# M3V4 register map
File version: 0.1
Registers are 32-bit, read-write, reset 0x0 unless marked. A register's access mark holds for its fields unless they carry their own. Offsets are from the block's base; [hi:lo] are bit positions; {n}, {i} and the like mark numbered series.

## PE — General Purpose Input_Output Port (PE)
Base 0x40000100
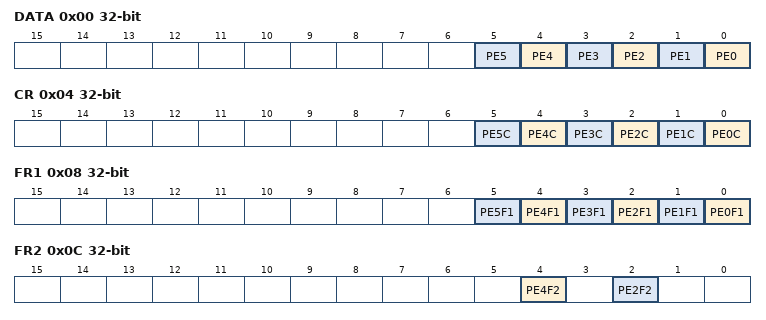
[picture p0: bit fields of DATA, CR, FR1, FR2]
0x00 DATA — PE Data Register
  [n] PE{n} (n=0..5)
0x04 CR — PE Control Register
  [n] PE{n}C (n=0..5)
0x08 FR1 — PE Function Register 1
  [n] PE{n}F1 (n=0..5)
0x0C FR2 — PE Function Register 2
  [4] PE4F2, [2] PE2F2
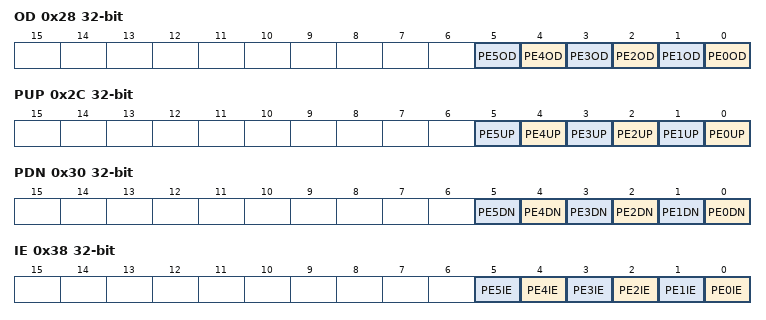
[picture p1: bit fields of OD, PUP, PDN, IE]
0x28 OD — PE Open Drain Control Register
  [n] PE{n}OD (n=0..5)
0x2C PUP — PE Pull-Up Control Register
  [n] PE{n}UP (n=0..5)
0x30 PDN — PE Pull-Down Control Register
  [n] PE{n}DN (n=0..5)
0x38 IE — PE Input Enable Control Register
  [n] PE{n}IE (n=0..5)

## PF — General Purpose Input_Output Port (PF)
Base 0x40000140
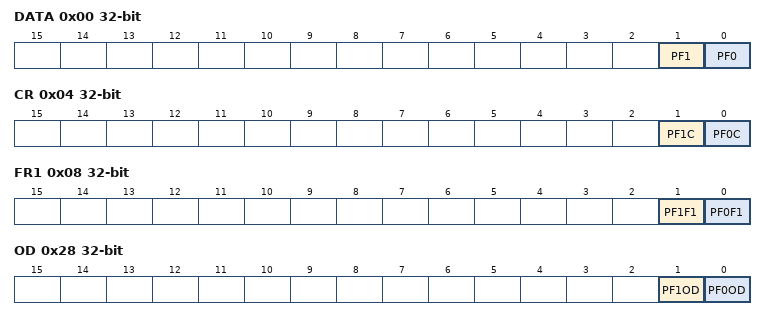
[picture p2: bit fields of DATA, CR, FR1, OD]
0x00 DATA — PF Data Register
  [1] PF1, [0] PF0
0x04 CR — PF Control Register
  [1] PF1C, [0] PF0C
0x08 FR1 — PF Function Register 1
  [1] PF1F1, [0] PF0F1
0x0C FR2 — PF Function Register 2
  [1] PF1F2
0x28 OD — PF Open Drain Control Register
  [1] PF1OD, [0] PF0OD
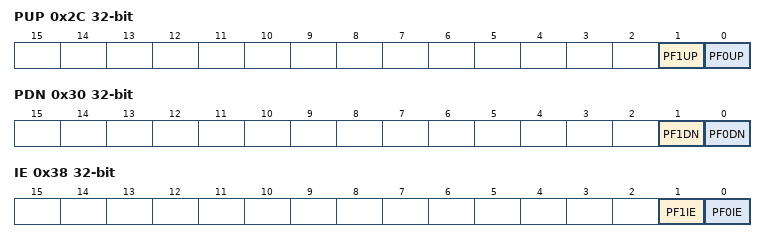
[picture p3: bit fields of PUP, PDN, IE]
0x2C PUP — PF Pull-Up Control Register
  [1] PF1UP, [0] PF0UP
0x30 PDN — PF Pull-Down Control Register
  [1] PF1DN, [0] PF0DN
0x38 IE — PF Input Enable Control Register
  [1] PF1IE, [0] PF0IE

## PH — General Purpose Input_Output Port (PH)
Base 0x400001C0
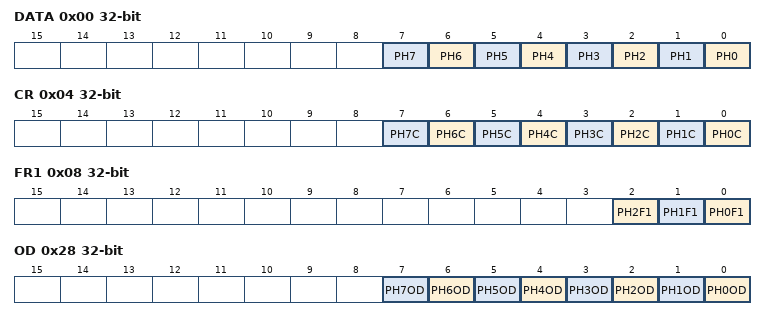
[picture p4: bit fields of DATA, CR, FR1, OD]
0x00 DATA — PH Data Register
  [n] PH{n} (n=0..7)
0x04 CR — PH Control Register
  [n] PH{n}C (n=0..7)
0x08 FR1 — PH Function Register 1
  [2] PH2F1, [1] PH1F1, [0] PH0F1
0x28 OD — PH Open Drain Control Register
  [n] PH{n}OD (n=0..7)
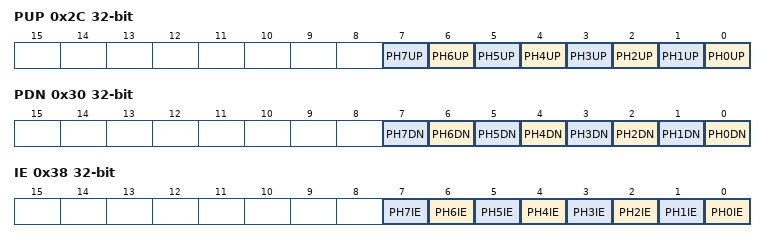
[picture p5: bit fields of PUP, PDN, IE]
0x2C PUP — PH Pull-Up Control Register
  [n] PH{n}UP (n=0..7)
0x30 PDN — PH Pull-Down Control Register
  [n] PH{n}DN (n=0..7)
0x38 IE — PH Input Enable Control Register
  [n] PH{n}IE (n=0..7)

## PI — General Purpose Input_Output Port (PI)
Base 0x40000200
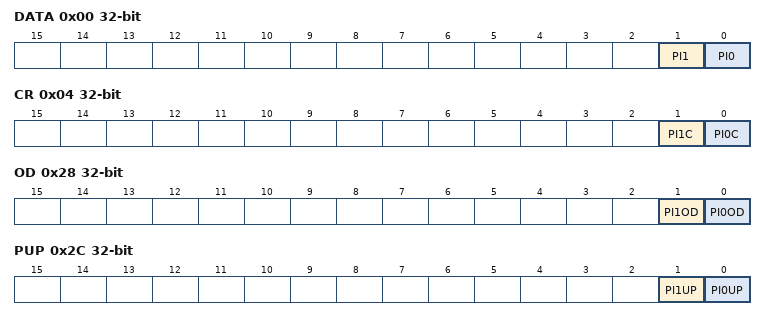
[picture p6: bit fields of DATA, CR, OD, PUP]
0x00 DATA — PI Data Register
  [1] PI1, [0] PI0
0x04 CR — PI Control Register
  [1] PI1C, [0] PI0C
0x28 OD — PI Open Drain Control Register
  [1] PI1OD, [0] PI0OD
0x2C PUP — PI Pull-Up Control Register
  [1] PI1UP, [0] PI0UP
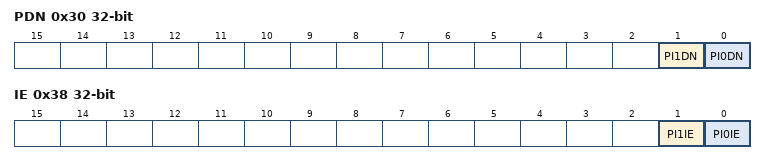
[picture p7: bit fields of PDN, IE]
0x30 PDN — PI Pull-Down Control Register
  [1] PI1DN, [0] PI0DN
0x38 IE — PI Input Enable Control Register
  [1] PI1IE, [0] PI0IE

## PL — General Purpose Input_Output Port (PL)
Base 0x400002C0
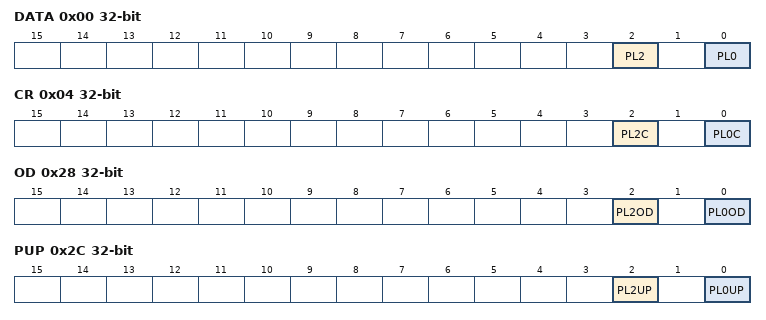
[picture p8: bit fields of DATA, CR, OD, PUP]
0x00 DATA — PL Data Register
  [2] PL2, [0] PL0
0x04 CR — PL Control Register
  [2] PL2C, [0] PL0C
0x08 FR1 — PL Function Register 1
  [2] PL2F1
0x28 OD — PL Open Drain Control Register
  [2] PL2OD, [0] PL0OD
0x2C PUP — PL Pull-Up Control Register
  [2] PL2UP, [0] PL0UP
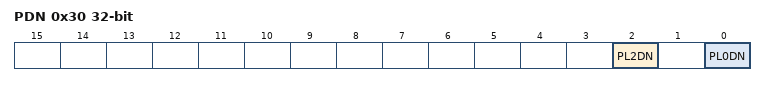
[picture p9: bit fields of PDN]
0x30 PDN — PL Pull-Down Control Register
  [2] PL2DN, [0] PL0DN
0x38 IE — PL Input Enable Control Register
  [2] PL2IE

## PM — General Purpose Input_Output Port (PM)
Base 0x40000300
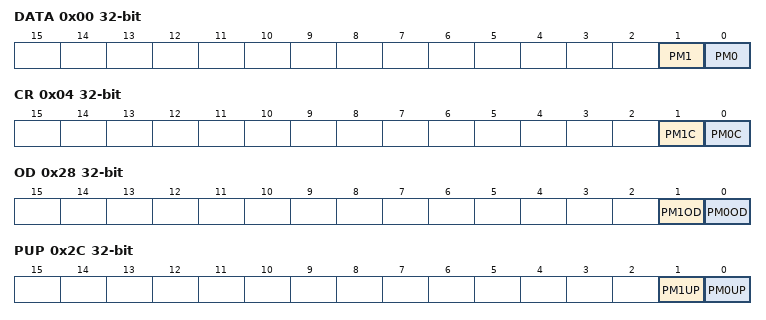
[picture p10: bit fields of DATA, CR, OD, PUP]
0x00 DATA — PM Data Register
  [1] PM1, [0] PM0
0x04 CR — PM Control Register
  [1] PM1C, [0] PM0C
0x28 OD — PM Open Drain Control Register
  [1] PM1OD, [0] PM0OD
0x2C PUP — PM Pull-Up Control Register
  [1] PM1UP, [0] PM0UP
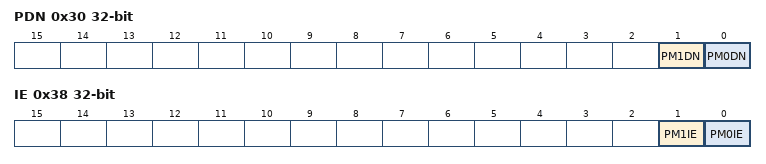
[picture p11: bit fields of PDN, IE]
0x30 PDN — PM Pull-Down Control Register
  [1] PM1DN, [0] PM0DN
0x38 IE — PM Input Enable Control Register
  [1] PM1IE, [0] PM0IE

## PP — General Purpose Input_Output Port (PP)
Base 0x40000380
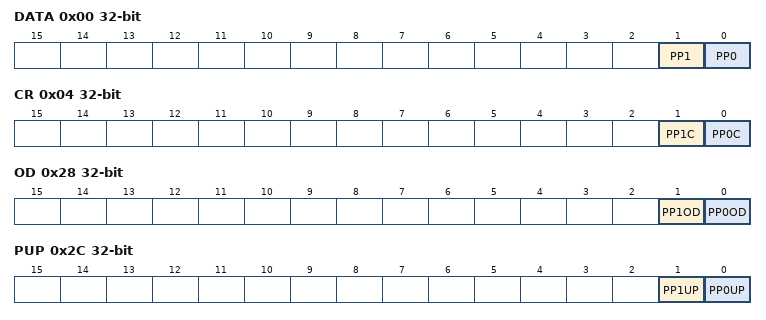
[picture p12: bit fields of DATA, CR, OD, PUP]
0x00 DATA — PP Data Register
  [1] PP1, [0] PP0
0x04 CR — PP Control Register
  [1] PP1C, [0] PP0C
0x28 OD — PP Open Drain Control Register
  [1] PP1OD, [0] PP0OD
0x2C PUP — PP Pull-Up Control Register
  [1] PP1UP, [0] PP0UP
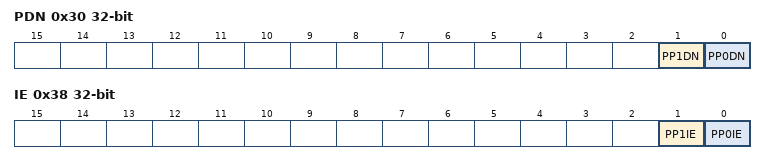
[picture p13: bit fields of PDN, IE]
0x30 PDN — PP Pull-Down Control Register
  [1] PP1DN, [0] PP0DN
0x38 IE — PP Input Enable Control Register
  [1] PP1IE, [0] PP0IE

## TB0 — 16-bit Timer_Event Counter (TB)
Base 0x40010000
Same registers: TB1 0x40010040, TB2 0x40010080, TB4 0x40010100, TB6 0x40010180, TB7 0x400101C0
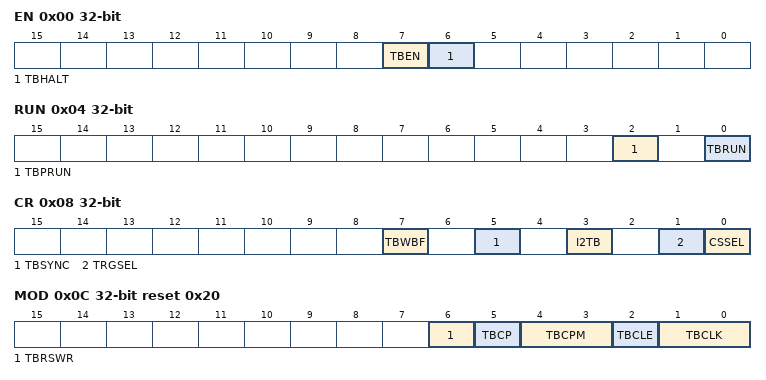
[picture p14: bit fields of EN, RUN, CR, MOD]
0x00 EN — TB Enable Register
  [7] TBEN, [6] TBHALT
0x04 RUN — TB RUN Register
  [2] TBPRUN, [0] TBRUN
0x08 CR — TB Control Register
  [7] TBWBF, [5] TBSYNC, [3] I2TB, [1] TRGSEL, [0] CSSEL
0x0C MOD reset 0x20 — TB Mode Register
  [6] TBRSWR, [5] TBCP wo, [4:3] TBCPM, [2] TBCLE, [1:0] TBCLK
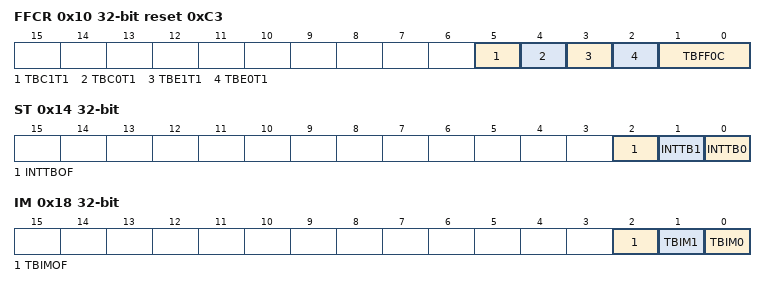
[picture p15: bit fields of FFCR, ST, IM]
0x10 FFCR reset 0xC3 — TB Flip-Flop Control Register
  [5] TBC1T1, [4] TBC0T1, [3] TBE1T1, [2] TBE0T1, [1:0] TBFF0C
0x14 ST ro — TB Status Register
  [2] INTTBOF, [1] INTTB1, [0] INTTB0
0x18 IM — TB Interrupt Mask Register
  [2] TBIMOF, [1] TBIM1, [0] TBIM0
0x1C UC ro — TB Read Capture Register
  [15:0] TBUC
0x20 RG0 — TB RG0 Timer Register
  [15:0] TBRG0
0x24 RG1 — TB RG1 Timer Register
  [15:0] TBRG1
0x28 CP0 ro (reset mask 0xFFFF0000) — TB CP0 Capture Register
  [15:0] TBCP0
0x2C CP1 ro (reset mask 0xFFFF0000) — TB CP1 Capture Register
  [15:0] TBCP1

## TB3 — 16-bit Timer_Event Counter (TB)
Base 0x400100C0
Same registers: TB5 0x40010140
Registers as TB0, without FFCR.
